# PIC32MK1024GPK064 device description
Architecture: MIPS; Family: PIC32MK; Series: PIC32MK
Registers are 32-bit, read-write, no defined reset value unless marked. A register's access mark holds for its fields unless they carry their own. Offsets are from the block's base; [hi:lo] are bit positions.

## RCON
Instances: RCON 0x1f801200 in periph_pb1_std
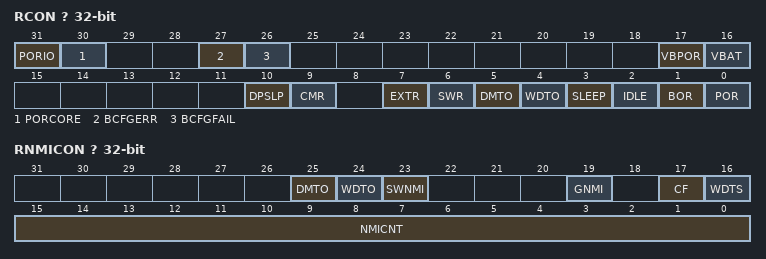
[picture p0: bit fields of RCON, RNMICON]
? RCON size not given access not given — Reset Control Register
  [31] PORIO — I/O Voltage POR Flag bit
    1=RESET (A Power-up Reset has occurred due to I/O Voltage); 0=NORESET (A Power-up Reset has not occurred due to I/O Voltage)
  [30] PORCORE — Core Voltage POR Flag bit
    1=RESET (A Power-up Reset has occurred due to Core Voltage); 0=NORESET (A Power-up Reset has not occurred due to Core Voltage)
  [27] BCFGERR — Primary Configuration Registers Error Flag bit
    1=ERROR (An error occurred during a read of the primary configuration registers); 0=NOERROR (No error occurred during a read of the primary configuration registers)
  [26] BCFGFAIL — Primary/Secondary Configuration Registers Error Flag bit
    1=ERROR (An error occurred during a read of the primary and alternate configuration registers); 0=NOERROR (No error occurred during a read of the primary and alternate configuration registers)
  [17] VBPOR — VBPOR Mode Flag bit
    1=POR (A VBAT domain POR has occurred); 0=NOPOR (A VBAT domain POR has not occurred)
  [16] VBAT — VBAT Mode Flag bit
    1=POR (A POR exit from VBAT has occurred); 0=NOPOR (A POR exit from VBAT has not occurred)
  [10] DPSLP — Deep Sleep Mode Flag bit
    1=SLEEP (Deep Sleep mode has occurred); 0=NOSLEEP (Deep Sleep mode has not occurred)
  [9] CMR — Configuration Mismatch Reset Flag bit
    1=RESET (A Configuration Mismatch Reset has occurred); 0=NORESET (A Configuration Mismatch Reset has not occurred)
  [7] EXTR — External Reset (MCLR) Pin Flag bit
    1=RESET (Master Clear (pin) Reset has occurred); 0=NORESET (Master Clear (pin) Reset has not occurred)
  [6] SWR — Software Reset Flag bit
    1=RESET (Software Reset was executed); 0=NORESET (Software Reset was not executed)
  [5] DMTO — Deadman Timer Time-out Flag bit
    1=TIMEOUT (A DMT time-out has occurred); 0=NOTIMEOUT (A DMT time-out has not occurred)
  [4] WDTO — Watchdog Timer Time-out Flag bit
    1=TIMEOUT (WDT Time-out has occurred); 0=NOTIMEOUT (WDT Time-out has not occurred)
  [3] SLEEP — Wake From Sleep Flag bit
    1=SLEEP (Device was in Sleep mode); 0=NOSLEEP (Device was not in Sleep mode)
  [2] IDLE — Wake From Idle Flag bit
    1=IDLE (Device was in Idle mode); 0=NOIDLE (Device was not in Idle mode)
  [1] BOR — Brown-out Reset Flag bit
    1=RESET (Brown-out Reset has occurred); 0=NORESET (Brown-out Reset has not occurred)
  [0] POR — Power-on Reset Flag bit
    1=RESET (Power-on Reset has occurred); 0=NORESET (Power-on Reset has NOT occurred)
? RSWRST size not given access not given — Software Reset Register
  [0] SWRST — Enable software Reset event
    1=RESET (Enable software Reset event); 0=NORESET (No effect)
? RNMICON size not given access not given — Non-maskable Interrupt Control Register
  [25] DMTO — Deadman Timer Time-out Flag bit
    1=TIMEOUT (DMT time-out has occurred and caused a NMI); 0=NO_TIMEOUT (DMT time-out has not occurred)
  [24] WDTO — Watchdog Timer Time-Out Flag bit
    1=TIMEOUT (WDT time-out has occurred and caused a NMI); 0=NO_TIMEOUT (WDT time-out has not occurred)
  [23] SWNMI — Software NMI Trigger
    1=GENERATE_NMI (An NMI will be generated); 0=NO_NMI (An NMI will not be generated)
  [19] GNMI — General NMI bit
    1=EVENT (A general NMI event has been detected or a user-initiated NMI event has occurred); 0=NOEVENT (A general NMI event has not been detected)
  [17] CF — Clock Fail Detect bit
    1=CLKFAIL (FSCM has detected clock failure and caused an NMI); 0=NOCKFAIL (FSCM has not detected clock failure)
  [16] WDTS — Watchdog Timer Time-out in Sleep Mode Flag bit
    1=TIMEOUT (WDT time-out has occurred during Sleep mode and caused a wake-up from sleep); 0=NOTIMEOUT (WDT time-out has not occurred during Sleep mode)
  [15:0] NMICNT — NMI Reset Counter Value bits
    0=NODELAY (No delay between NMI assertion and device Reset event)
? PWRCON size not given access not given — Power Control Register
  [0] VREGS — Internal Voltage Regulator Stand-by Enable bit
    1=ACTIVE (Voltage regulator will remain active during Sleep); 0=STANDBY (Voltage regulator will go to Stand-by mode during Sleep)

## Notices in the file
Copyright (c) 2019 Microchip Technology Inc.
SPDX-License-Identifier: Apache-2.0
Licensed under the Apache License, Version 2.0 (the "License");
you may not use this file except in compliance with the License.
You may obtain a copy of the License at
http://www.apache.org/licenses/LICENSE-2.0
Unless required by applicable law or agreed to in writing, software
distributed under the License is distributed on an "AS IS" BASIS,
WITHOUT WARRANTIES OR CONDITIONS OF ANY KIND, either express or implied.
See the License for the specific language governing permissions and
limitations under the License.
